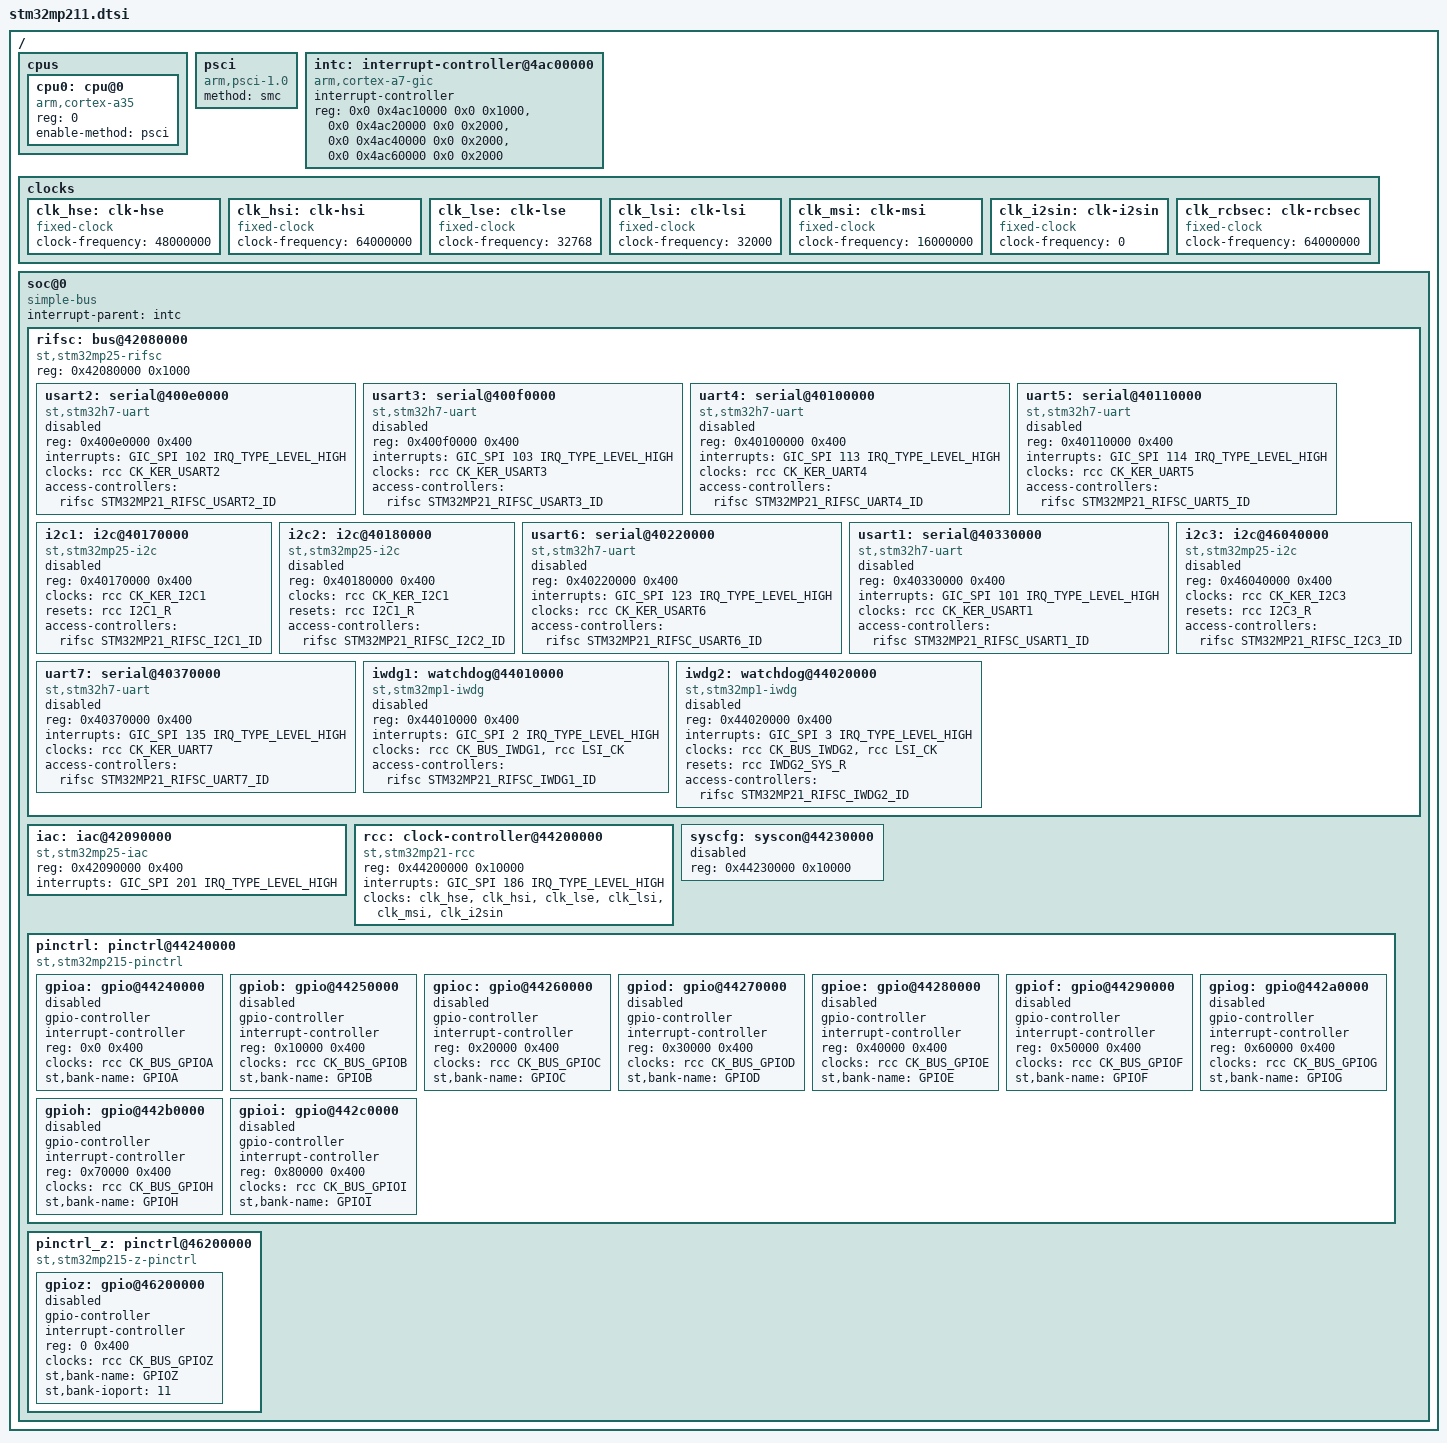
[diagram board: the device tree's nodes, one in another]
// SPDX-License-Identifier: (GPL-2.0-only OR BSD-3-Clause)
/*
 * Copyright (C) 2025, STMicroelectronics - All Rights Reserved
 * Author: Alexandre Torgue <alexandre.torgue@foss.st.com> for STMicroelectronics.
 */
#include <dt-bindings/clock/st,stm32mp21-rcc.h>
#include <dt-bindings/gpio/gpio.h>
#include <dt-bindings/interrupt-controller/arm-gic.h>
#include <dt-bindings/firewall/stm32mp21-rifsc.h>
#include <dt-bindings/firewall/stm32mp25-rif.h>
#include <dt-bindings/firewall/stm32mp25-risab.h>
#include <dt-bindings/firewall/stm32mp25-risaf.h>
#include <dt-bindings/reset/st,stm32mp21-rcc.h>

/ {
	#address-cells = <2>;
	#size-cells = <2>;

	cpus {
		#address-cells = <1>;
		#size-cells = <0>;

		cpu0: cpu@0 {
			compatible = "arm,cortex-a35";
			device_type = "cpu";
			reg = <0>;
			enable-method = "psci";
		};
	};

	psci {
		compatible = "arm,psci-1.0";
		method = "smc";
	};

	intc: interrupt-controller@4ac00000 {
		compatible = "arm,cortex-a7-gic";
		#interrupt-cells = <3>;
		interrupt-controller;
		reg = <0x0 0x4ac10000 0x0 0x1000>,
		      <0x0 0x4ac20000 0x0 0x2000>,
		      <0x0 0x4ac40000 0x0 0x2000>,
		      <0x0 0x4ac60000 0x0 0x2000>;
		#address-cells = <1>;
	};

	clocks {
		clk_hse: clk-hse {
			#clock-cells = <0>;
			compatible = "fixed-clock";
			clock-frequency = <48000000>;
		};

		clk_hsi: clk-hsi {
			#clock-cells = <0>;
			compatible = "fixed-clock";
			clock-frequency = <64000000>;
		};

		clk_lse: clk-lse {
			#clock-cells = <0>;
			compatible = "fixed-clock";
			clock-frequency = <32768>;
		};

		clk_lsi: clk-lsi {
			#clock-cells = <0>;
			compatible = "fixed-clock";
			clock-frequency = <32000>;
		};

		clk_msi: clk-msi {
			#clock-cells = <0>;
			compatible = "fixed-clock";
			clock-frequency = <16000000>;
		};

		clk_i2sin: clk-i2sin {
			#clock-cells = <0>;
			compatible = "fixed-clock";
			clock-frequency = <0>;
		};

		clk_rcbsec: clk-rcbsec {
			#clock-cells = <0>;
			compatible = "fixed-clock";
			clock-frequency = <64000000>;
		};
	};

	soc@0 {
		compatible = "simple-bus";
		#address-cells = <1>;
		#size-cells = <1>;
		interrupt-parent = <&intc>;
		ranges = <0x0 0x0 0x0 0x80000000>;

		rifsc: bus@42080000 {
			compatible = "st,stm32mp25-rifsc", "simple-bus";
			reg = <0x42080000 0x1000>;
			#address-cells = <1>;
			#size-cells = <1>;
			#access-controller-cells = <1>;

			usart2: serial@400e0000 {
				compatible = "st,stm32h7-uart";
				reg = <0x400e0000 0x400>;
				interrupts = <GIC_SPI 102 IRQ_TYPE_LEVEL_HIGH>;
				clocks = <&rcc CK_KER_USART2>;
				access-controllers = <&rifsc STM32MP21_RIFSC_USART2_ID>;
				status = "disabled";
			};

			usart3: serial@400f0000 {
				compatible = "st,stm32h7-uart";
				reg = <0x400f0000 0x400>;
				interrupts = <GIC_SPI 103 IRQ_TYPE_LEVEL_HIGH>;
				clocks = <&rcc CK_KER_USART3>;
				access-controllers = <&rifsc STM32MP21_RIFSC_USART3_ID>;
				status = "disabled";
			};

			uart4: serial@40100000 {
				compatible = "st,stm32h7-uart";
				reg = <0x40100000 0x400>;
				interrupts = <GIC_SPI 113 IRQ_TYPE_LEVEL_HIGH>;
				clocks = <&rcc CK_KER_UART4>;
				access-controllers = <&rifsc STM32MP21_RIFSC_UART4_ID>;
				status = "disabled";
			};

			uart5: serial@40110000 {
				compatible = "st,stm32h7-uart";
				reg = <0x40110000 0x400>;
				interrupts = <GIC_SPI 114 IRQ_TYPE_LEVEL_HIGH>;
				clocks = <&rcc CK_KER_UART5>;
				access-controllers = <&rifsc STM32MP21_RIFSC_UART5_ID>;
				status = "disabled";
			};

			i2c1: i2c@40170000 {
				compatible = "st,stm32mp25-i2c";
				reg = <0x40170000 0x400>;
				clocks = <&rcc CK_KER_I2C1>;
				resets = <&rcc I2C1_R>;
				#address-cells = <1>;
				#size-cells = <0>;
				access-controllers = <&rifsc STM32MP21_RIFSC_I2C1_ID>;
				status = "disabled";
			};

			i2c2: i2c@40180000 {
				compatible = "st,stm32mp25-i2c";
				reg = <0x40180000 0x400>;
				clocks = <&rcc CK_KER_I2C1>;
				resets = <&rcc I2C1_R>;
				#address-cells = <1>;
				#size-cells = <0>;
				access-controllers = <&rifsc STM32MP21_RIFSC_I2C2_ID>;
				status = "disabled";
			};

			usart6: serial@40220000 {
				compatible = "st,stm32h7-uart";
				reg = <0x40220000 0x400>;
				interrupts = <GIC_SPI 123 IRQ_TYPE_LEVEL_HIGH>;
				clocks = <&rcc CK_KER_USART6>;
				access-controllers = <&rifsc STM32MP21_RIFSC_USART6_ID>;
				status = "disabled";
			};

			usart1: serial@40330000 {
				compatible = "st,stm32h7-uart";
				reg = <0x40330000 0x400>;
				interrupts = <GIC_SPI 101 IRQ_TYPE_LEVEL_HIGH>;
				clocks = <&rcc CK_KER_USART1>;
				access-controllers = <&rifsc STM32MP21_RIFSC_USART1_ID>;
				status = "disabled";
			};

			uart7: serial@40370000 {
				compatible = "st,stm32h7-uart";
				reg = <0x40370000 0x400>;
				interrupts = <GIC_SPI 135 IRQ_TYPE_LEVEL_HIGH>;
				clocks = <&rcc CK_KER_UART7>;
				access-controllers = <&rifsc STM32MP21_RIFSC_UART7_ID>;
				status = "disabled";
			};

			iwdg1: watchdog@44010000 {
				compatible = "st,stm32mp1-iwdg";
				reg = <0x44010000 0x400>;
				interrupts = <GIC_SPI 2 IRQ_TYPE_LEVEL_HIGH>;
				clocks = <&rcc CK_BUS_IWDG1>, <&rcc LSI_CK>;
				clock-names = "pclk", "lsi";
				access-controllers = <&rifsc STM32MP21_RIFSC_IWDG1_ID>;
				status = "disabled";
			};

			iwdg2: watchdog@44020000 {
				compatible = "st,stm32mp1-iwdg";
				reg = <0x44020000 0x400>;
				interrupts = <GIC_SPI 3 IRQ_TYPE_LEVEL_HIGH>;
				clocks = <&rcc CK_BUS_IWDG2>, <&rcc LSI_CK>;
				clock-names = "pclk", "lsi";
				resets = <&rcc IWDG2_SYS_R>;
				access-controllers = <&rifsc STM32MP21_RIFSC_IWDG2_ID>;
				status = "disabled";
			};

			i2c3: i2c@46040000 {
				compatible = "st,stm32mp25-i2c";
				reg = <0x46040000 0x400>;
				clocks = <&rcc CK_KER_I2C3>;
				resets = <&rcc I2C3_R>;
				#address-cells = <1>;
				#size-cells = <0>;
				access-controllers = <&rifsc STM32MP21_RIFSC_I2C3_ID>;
				status = "disabled";
			};
		};

		iac: iac@42090000 {
			compatible = "st,stm32mp25-iac";
			reg = <0x42090000 0x400>;
			interrupts = <GIC_SPI 201 IRQ_TYPE_LEVEL_HIGH>;
		};

		rcc: clock-controller@44200000 {
			compatible = "st,stm32mp21-rcc", "syscon";
			reg = <0x44200000 0x10000>;
			interrupts = <GIC_SPI 186 IRQ_TYPE_LEVEL_HIGH>;

			#clock-cells = <1>;
			#reset-cells = <1>;
			clocks = <&clk_hse>, <&clk_hsi>, <&clk_lse>,
				 <&clk_lsi>, <&clk_msi>, <&clk_i2sin>;
			clock-names = "clk-hse", "clk-hsi", "clk-lse",
				      "clk-lsi", "clk-msi", "clk-i2sin";
		};

		syscfg: syscon@44230000 {
			reg = <0x44230000 0x10000>;
			status = "disabled";
		};

		pinctrl: pinctrl@44240000 {
			#address-cells = <1>;
			#size-cells = <1>;
			compatible = "st,stm32mp215-pinctrl";
			ranges = <0 0x44240000 0x80400>;

			gpioa: gpio@44240000 {
				gpio-controller;
				#gpio-cells = <2>;
				interrupt-controller;
				#interrupt-cells = <2>;
				#access-controller-cells = <1>;
				reg = <0x0 0x400>;
				clocks = <&rcc CK_BUS_GPIOA>;
				st,bank-name = "GPIOA";
				status = "disabled";
			};

			gpiob: gpio@44250000 {
				gpio-controller;
				#gpio-cells = <2>;
				interrupt-controller;
				#interrupt-cells = <2>;
				#access-controller-cells = <1>;
				reg = <0x10000 0x400>;
				clocks = <&rcc CK_BUS_GPIOB>;
				st,bank-name = "GPIOB";
				status = "disabled";
			};

			gpioc: gpio@44260000 {
				gpio-controller;
				#gpio-cells = <2>;
				interrupt-controller;
				#interrupt-cells = <2>;
				#access-controller-cells = <1>;
				reg = <0x20000 0x400>;
				clocks = <&rcc CK_BUS_GPIOC>;
				st,bank-name = "GPIOC";
				status = "disabled";
			};

			gpiod: gpio@44270000 {
				gpio-controller;
				#gpio-cells = <2>;
				interrupt-controller;
				#interrupt-cells = <2>;
				#access-controller-cells = <1>;
				reg = <0x30000 0x400>;
				clocks = <&rcc CK_BUS_GPIOD>;
				st,bank-name = "GPIOD";
				status = "disabled";
			};

			gpioe: gpio@44280000 {
				gpio-controller;
				#gpio-cells = <2>;
				interrupt-controller;
				#interrupt-cells = <2>;
				#access-controller-cells = <1>;
				reg = <0x40000 0x400>;
				clocks = <&rcc CK_BUS_GPIOE>;
				st,bank-name = "GPIOE";
				status = "disabled";
			};

			gpiof: gpio@44290000 {
				gpio-controller;
				#gpio-cells = <2>;
				interrupt-controller;
				#interrupt-cells = <2>;
				#access-controller-cells = <1>;
				reg = <0x50000 0x400>;
				clocks = <&rcc CK_BUS_GPIOF>;
				st,bank-name = "GPIOF";
				status = "disabled";
			};

			gpiog: gpio@442a0000 {
				gpio-controller;
				#gpio-cells = <2>;
				interrupt-controller;
				#interrupt-cells = <2>;
				#access-controller-cells = <1>;
				reg = <0x60000 0x400>;
				clocks = <&rcc CK_BUS_GPIOG>;
				st,bank-name = "GPIOG";
				status = "disabled";
			};

			gpioh: gpio@442b0000 {
				gpio-controller;
				#gpio-cells = <2>;
				interrupt-controller;
				#interrupt-cells = <2>;
				#access-controller-cells = <1>;
				reg = <0x70000 0x400>;
				clocks = <&rcc CK_BUS_GPIOH>;
				st,bank-name = "GPIOH";
				status = "disabled";
			};

			gpioi: gpio@442c0000 {
				gpio-controller;
				#gpio-cells = <2>;
				interrupt-controller;
				#interrupt-cells = <2>;
				#access-controller-cells = <1>;
				reg = <0x80000 0x400>;
				clocks = <&rcc CK_BUS_GPIOI>;
				st,bank-name = "GPIOI";
				status = "disabled";
			};
		};

		pinctrl_z: pinctrl@46200000 {
			#address-cells = <1>;
			#size-cells = <1>;
			compatible = "st,stm32mp215-z-pinctrl";
			ranges = <0 0x46200000 0x400>;

			gpioz: gpio@46200000 {
				gpio-controller;
				#gpio-cells = <2>;
				interrupt-controller;
				#interrupt-cells = <2>;
				#access-controller-cells = <1>;
				reg = <0 0x400>;
				clocks = <&rcc CK_BUS_GPIOZ>;
				st,bank-name = "GPIOZ";
				st,bank-ioport = <11>;
				status = "disabled";
			};
		};
	};
};
